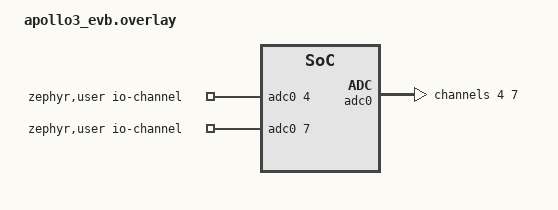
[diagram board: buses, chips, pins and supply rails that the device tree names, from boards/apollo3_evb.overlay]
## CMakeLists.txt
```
# Copyright (c) 2022 Microchip Technology Inc.
#
# SPDX-License-Identifier: Apache-2.0
#
cmake_minimum_required(VERSION 3.20.0)

find_package(Zephyr REQUIRED HINTS $ENV{ZEPHYR_BASE})
project(ambiq_adc_test)

FILE(GLOB app_sources src/*.c)
target_sources(app PRIVATE ${app_sources})
```

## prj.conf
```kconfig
CONFIG_STDOUT_CONSOLE=y
CONFIG_ADC=y
CONFIG_NO_OPTIMIZATIONS=y
CONFIG_MAIN_STACK_SIZE=4096
```

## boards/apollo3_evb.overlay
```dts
/*
 * Copyright (c) 2024 Ambiq Micro Inc.
 *
 * SPDX-License-Identifier: Apache-2.0
 */
/ {
	zephyr,user {
		io-channels = <&adc0 4>, <&adc0 7>;
	};
};

&adc0 {
	status = "okay";
	interrupt-parent = <&nvic>;
	interrupts = <18 0>;
	#address-cells = <1>;
	#size-cells = <0>;

	channel@4 {
		reg = <4>;
		zephyr,gain = "ADC_GAIN_1";
		zephyr,reference = "ADC_REF_INTERNAL";
		zephyr,acquisition-time = <ADC_ACQ_TIME_DEFAULT>;
		zephyr,resolution = <14>;
	};

	channel@7 {
		reg = <7>;
		zephyr,gain = "ADC_GAIN_1";
		zephyr,reference = "ADC_REF_INTERNAL";
		zephyr,acquisition-time = <ADC_ACQ_TIME_DEFAULT>;
		zephyr,resolution = <14>;
	};
};
```

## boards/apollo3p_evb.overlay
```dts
/*
 * Copyright (c) 2024 Ambiq Micro Inc.
 *
 * SPDX-License-Identifier: Apache-2.0
 */
/ {
	zephyr,user {
		io-channels = <&adc0 4>, <&adc0 7>;
	};
};

&adc0 {
	status = "okay";
	interrupt-parent = <&nvic>;
	interrupts = <18 0>;
	#address-cells = <1>;
	#size-cells = <0>;

	channel@4 {
		reg = <4>;
		zephyr,gain = "ADC_GAIN_1";
		zephyr,reference = "ADC_REF_INTERNAL";
		zephyr,acquisition-time = <0>;
		zephyr,resolution = <14>;
	};

	channel@7 {
		reg = <7>;
		zephyr,gain = "ADC_GAIN_1";
		zephyr,reference = "ADC_REF_INTERNAL";
		zephyr,acquisition-time = <0>;
		zephyr,resolution = <14>;
	};
};
```

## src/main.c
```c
/*
 * Copyright (c) 2020 Libre Solar Technologies GmbH
 *
 * SPDX-License-Identifier: Apache-2.0
 */

#include <zephyr/kernel.h>
#include <zephyr/device.h>
#include <zephyr/devicetree.h>
#include <zephyr/drivers/adc.h>
#include <zephyr/sys/printk.h>

#define SLEEP_TIME_MS   2000

#if !DT_NODE_EXISTS(DT_PATH(zephyr_user)) || \
	!DT_NODE_HAS_PROP(DT_PATH(zephyr_user), io_channels)
#error "No suitable devicetree overlay specified"
#endif

#define DT_SPEC_AND_COMMA(node_id, prop, idx) \
	ADC_DT_SPEC_GET_BY_IDX(node_id, idx),

/* Data of ADC io-channels specified in devicetree. */
static const struct adc_dt_spec adc_channels[] = {
	DT_FOREACH_PROP_ELEM(DT_PATH(zephyr_user), io_channels,
			     DT_SPEC_AND_COMMA)
};


int main(void) {
  int err;
  uint32_t count = 0;
  uint16_t buf;
  struct adc_sequence sequence = {
      .buffer = &buf,
      /* buffer size in bytes, not number of samples */
      .buffer_size = sizeof(buf),
  };

  /* Configure channels individually prior to sampling. */
  for (size_t i = 0U; i < ARRAY_SIZE(adc_channels); i++) {
    if (!adc_is_ready_dt(&adc_channels[i])) {
      printk("ADC controller device %s not ready\n", adc_channels[i].dev->name);
      return 0;
    }

    err = adc_channel_setup_dt(&adc_channels[i]);
    if (err < 0) {
      printk("Could not setup channel #%d (%d)\n", i, err);
      return 0;
    }
  }

  while (1) {
    printk("ADC reading[%u]:\n", count++);
    for (size_t i = 0U; i < ARRAY_SIZE(adc_channels); i++) {
      int32_t val_mv;

      printk("- %s, channel %d: ", adc_channels[i].dev->name,
             adc_channels[i].channel_id);

      (void)adc_sequence_init_dt(&adc_channels[i], &sequence);

      err = adc_read_dt(&adc_channels[i], &sequence);
      if (err < 0) {
        printk("Could not read (%d)\n", err);
        continue;
      }

      /*
       * If using differential mode, the 16 bit value
       * in the ADC sample buffer should be a signed 2's
       * complement value.
       */
      if (adc_channels[i].channel_cfg.differential) {
        val_mv = (int32_t)((int16_t)buf);
      } else {
        val_mv = (int32_t)buf;
      }
      printk("%" PRId32, val_mv);
      err = adc_raw_to_millivolts_dt(&adc_channels[i], &val_mv);
      /* conversion to mV may not be supported, skip if not */
      if (err < 0) {
        printk(" (value in mV not available)\n");
      } else {
        printk(" = %" PRId32 " mV\n", val_mv);
      }
    }

    k_sleep(K_MSEC(1000));
  }
  return 0;
}
```
